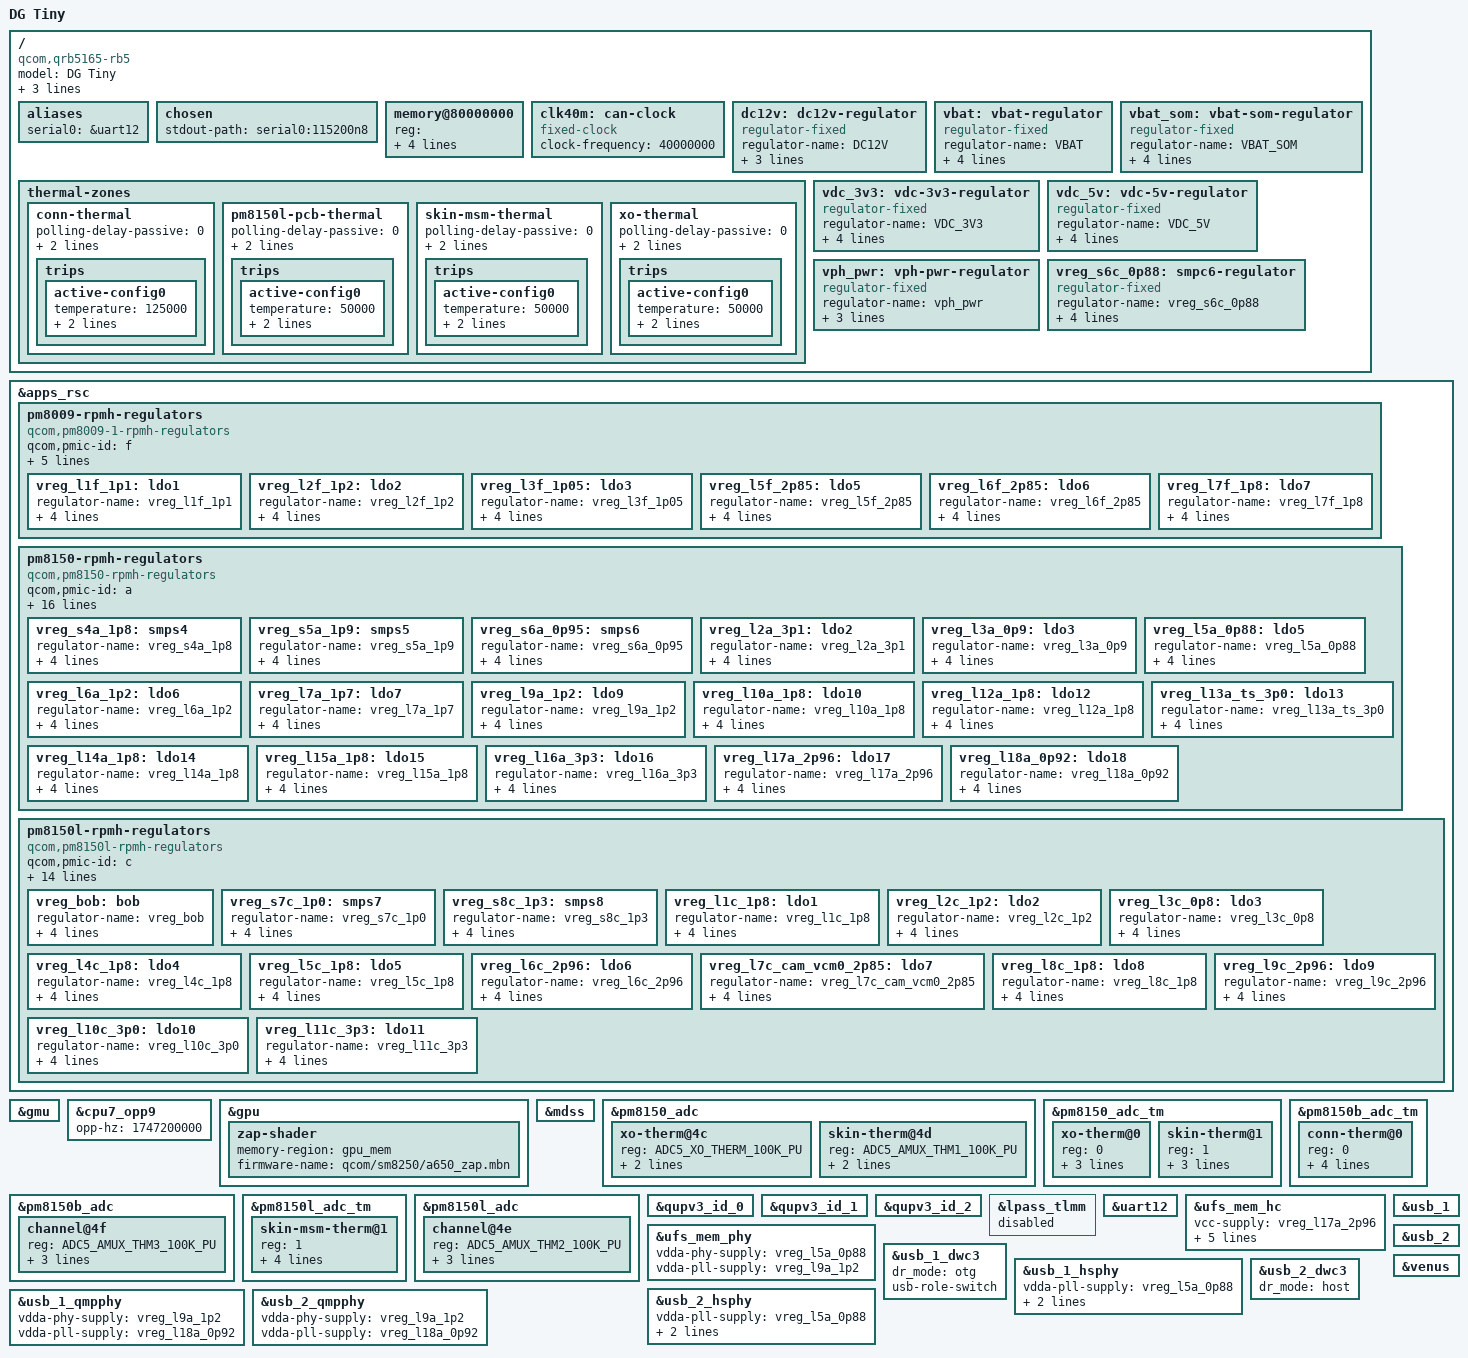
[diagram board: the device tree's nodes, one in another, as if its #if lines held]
// SPDX-License-Identifier: BSD-3-Clause

/dts-v1/;

#include <dt-bindings/regulator/qcom,rpmh-regulator.h>
#include <dt-bindings/leds/common.h>
#include <dt-bindings/pinctrl/qcom,pmic-gpio.h>
#include <dt-bindings/sound/qcom,q6afe.h>
#include <dt-bindings/sound/qcom,q6asm.h>
#include <dt-bindings/gpio/gpio.h>
#include "sm8250.dtsi"
#include "pm8150.dtsi"
#include "pm8150b.dtsi"
#include "pm8150l.dtsi"
#include "pm8009.dtsi"

/ {
	model = "DG Tiny";
	compatible = "qcom,qrb5165-rb5", "qcom,sm8250";
	qcom,msm-id = <455 0x20001>;
	qcom,board-id = <11 3>;
	chassis-type = "embedded";

	aliases {
		serial0 = &uart12;
	};

	chosen {
		stdout-path = "serial0:115200n8";
	};

#ifdef CONFIG_SYS_PROMPT
	memory@80000000 {
		device_type = "memory";
		reg = <0x00000000 0x80000000 0x00000000 0x39600000>, // 918 MB @ 0x80000000
			  <0x00000000 0xC0000000 0x00000000 0x14000000>, // 320 MB @ 0xC0000000
			  <0x00000001 0x00000000 0x00000001 0x30000000>, // 4.5 GB @ 0x100000000
			  <0x00000002 0x00000000 0x00000001 0x80000000>; // 6 GB @ 0x200000000
	};
#endif

	/* Fixed crystal oscillator dedicated to MCP2518FD */
	clk40m: can-clock {
		compatible = "fixed-clock";
		#clock-cells = <0>;
		clock-frequency = <40000000>;
	};

	dc12v: dc12v-regulator {
		compatible = "regulator-fixed";
		regulator-name = "DC12V";
		regulator-min-microvolt = <12000000>;
		regulator-max-microvolt = <12000000>;
		regulator-always-on;
	};

	thermal-zones {
		conn-thermal {
			polling-delay-passive = <0>;
			polling-delay = <0>;
			thermal-sensors = <&pm8150b_adc_tm 0>;

			trips {
				active-config0 {
					temperature = <125000>;
					hysteresis = <1000>;
					type = "critical";
				};
			};
		};

		pm8150l-pcb-thermal {
			polling-delay-passive = <0>;
			polling-delay = <0>;
			thermal-sensors = <&pm8150l_adc_tm 1>;

			trips {
				active-config0 {
					temperature = <50000>;
					hysteresis = <4000>;
					type = "passive";
				};
			};
		};

		skin-msm-thermal {
			polling-delay-passive = <0>;
			polling-delay = <0>;
			thermal-sensors = <&pm8150l_adc_tm 0>;

			trips {
				active-config0 {
					temperature = <50000>;
					hysteresis = <4000>;
					type = "passive";
				};
			};
		};

		xo-thermal {
			polling-delay-passive = <0>;
			polling-delay = <0>;
			thermal-sensors = <&pm8150_adc_tm 0>;

			trips {
				active-config0 {
					temperature = <50000>;
					hysteresis = <4000>;
					type = "passive";
				};
			};
		};
	};

	vbat: vbat-regulator {
		compatible = "regulator-fixed";
		regulator-name = "VBAT";
		vin-supply = <&vreg_l11c_3p3>;
		regulator-min-microvolt = <4200000>;
		regulator-max-microvolt = <4200000>;
		regulator-always-on;
	};

	vbat_som: vbat-som-regulator {
		compatible = "regulator-fixed";
		regulator-name = "VBAT_SOM";
		vin-supply = <&dc12v>;
		regulator-min-microvolt = <4200000>;
		regulator-max-microvolt = <4200000>;
		regulator-always-on;
	};

	vdc_3v3: vdc-3v3-regulator {
		compatible = "regulator-fixed";
		regulator-name = "VDC_3V3";
		vin-supply = <&vreg_l11c_3p3>;
		regulator-min-microvolt = <3300000>;
		regulator-max-microvolt = <3300000>;
		regulator-always-on;
	};

	vdc_5v: vdc-5v-regulator {
		compatible = "regulator-fixed";
		regulator-name = "VDC_5V";

		regulator-min-microvolt = <5000000>;
		regulator-max-microvolt = <5000000>;
		regulator-always-on;
		vin-supply = <&vreg_l11c_3p3>;
	};

	vph_pwr: vph-pwr-regulator {
		compatible = "regulator-fixed";
		regulator-name = "vph_pwr";
		regulator-min-microvolt = <3700000>;
		regulator-max-microvolt = <3700000>;
		regulator-always-on;
	};
/*
	vreg_s4a_1p8: vreg-s4a-1p8 {
		compatible = "regulator-fixed";
		regulator-name = "vreg_s4a_1p8";
		regulator-min-microvolt = <1800000>;
		regulator-max-microvolt = <1800000>;
		regulator-always-on;
	};
*/
	vreg_s6c_0p88: smpc6-regulator {
		compatible = "regulator-fixed";
		regulator-name = "vreg_s6c_0p88";

		regulator-min-microvolt = <880000>;
		regulator-max-microvolt = <880000>;
		regulator-always-on;
		vin-supply = <&vph_pwr>;
	};
};

&apps_rsc {
	pm8009-rpmh-regulators {
		compatible = "qcom,pm8009-1-rpmh-regulators";
		qcom,pmic-id = "f";

		vdd-s1-supply = <&vph_pwr>;
		vdd-s2-supply = <&vph_pwr>;
		vdd-l2-supply = <&vreg_s8c_1p3>;
		vdd-l5-l6-supply = <&vreg_bob>;
		vdd-l7-supply = <&vreg_s4a_1p8>;

		vreg_l1f_1p1: ldo1 {
			regulator-name = "vreg_l1f_1p1"; // bsp
			regulator-min-microvolt = <1104000>;
			regulator-max-microvolt = <1104000>;
			regulator-initial-mode = <RPMH_REGULATOR_MODE_HPM>;
		};

		vreg_l2f_1p2: ldo2 {
			regulator-name = "vreg_l2f_1p2"; // bsp
			regulator-min-microvolt = <1200000>;
			regulator-max-microvolt = <1200000>;
			regulator-initial-mode = <RPMH_REGULATOR_MODE_HPM>;
		};

		vreg_l3f_1p05: ldo3 {
			regulator-name = "vreg_l3f_1p05"; // bsp
			regulator-min-microvolt = <1056000>;
			regulator-max-microvolt = <1056000>;
			regulator-initial-mode = <RPMH_REGULATOR_MODE_HPM>;
		};

		vreg_l5f_2p85: ldo5 {
			regulator-name = "vreg_l5f_2p85"; // bsp
			regulator-min-microvolt = <2800000>;
			regulator-max-microvolt = <3000000>;
			regulator-initial-mode = <RPMH_REGULATOR_MODE_HPM>;
		};

		vreg_l6f_2p85: ldo6 {
			regulator-name = "vreg_l6f_2p85"; // bsp
			regulator-min-microvolt = <2800000>;
			regulator-max-microvolt = <3000000>;
			regulator-initial-mode = <RPMH_REGULATOR_MODE_HPM>;
		};

		vreg_l7f_1p8: ldo7 {
			regulator-name = "vreg_l7f_1p8"; // bsp
			regulator-min-microvolt = <1800000>;
			regulator-max-microvolt = <1800000>;
			regulator-initial-mode = <RPMH_REGULATOR_MODE_HPM>;
		};
	};

	pm8150-rpmh-regulators {
		compatible = "qcom,pm8150-rpmh-regulators";
		qcom,pmic-id = "a";

		vdd-s1-supply = <&vph_pwr>;
		vdd-s2-supply = <&vph_pwr>;
		vdd-s3-supply = <&vph_pwr>;
		vdd-s4-supply = <&vph_pwr>;
		vdd-s5-supply = <&vph_pwr>;
		vdd-s6-supply = <&vph_pwr>;
		vdd-s7-supply = <&vph_pwr>;
		vdd-s8-supply = <&vph_pwr>;
		vdd-s9-supply = <&vph_pwr>;
		vdd-s10-supply = <&vph_pwr>;
		vdd-l1-l8-l11-supply = <&vreg_s6c_0p88>;
		vdd-l2-l10-supply = <&vreg_bob>;
		vdd-l3-l4-l5-l18-supply = <&vreg_s6a_0p95>;
		vdd-l6-l9-supply = <&vreg_s8c_1p3>;
		vdd-l7-l12-l14-l15-supply = <&vreg_s5a_1p9>;
		vdd-l13-l16-l17-supply = <&vreg_bob>;

		vreg_s4a_1p8: smps4 {
			regulator-name = "vreg_s4a_1p8"; // bsp
			regulator-min-microvolt = <1800000>;
			regulator-max-microvolt = <1920000>;
			regulator-initial-mode = <RPMH_REGULATOR_MODE_HPM>;
		};

		vreg_s5a_1p9: smps5 {
			regulator-name = "vreg_s5a_1p9"; // bsp
			regulator-min-microvolt = <1824000>;
			regulator-max-microvolt = <2040000>;
			regulator-initial-mode = <RPMH_REGULATOR_MODE_HPM>;
		};

		vreg_s6a_0p95: smps6 {
			regulator-name = "vreg_s6a_0p95"; // bsp
			regulator-min-microvolt = <600000>;
			regulator-max-microvolt = <1128000>;
			regulator-initial-mode = <RPMH_REGULATOR_MODE_HPM>;
		};

		vreg_l2a_3p1: ldo2 {
			regulator-name = "vreg_l2a_3p1"; // bsp
			regulator-min-microvolt = <3072000>;
			regulator-max-microvolt = <3072000>;
			regulator-initial-mode = <RPMH_REGULATOR_MODE_HPM>;
		};

		vreg_l3a_0p9: ldo3 {
			regulator-name = "vreg_l3a_0p9"; // bsp
			regulator-min-microvolt = <928000>;
			regulator-max-microvolt = <932000>;
			regulator-initial-mode = <RPMH_REGULATOR_MODE_HPM>;
		};

		vreg_l5a_0p88: ldo5 {
			regulator-name = "vreg_l5a_0p88"; // bsp
			regulator-min-microvolt = <880000>;
			regulator-max-microvolt = <880000>;
			regulator-initial-mode = <RPMH_REGULATOR_MODE_HPM>;
		};

		vreg_l6a_1p2: ldo6 {
			regulator-name = "vreg_l6a_1p2"; // bsp
			regulator-min-microvolt = <1200000>;
			regulator-max-microvolt = <1200000>;
			regulator-initial-mode = <RPMH_REGULATOR_MODE_HPM>;
		};

		vreg_l7a_1p7: ldo7 {
			regulator-name = "vreg_l7a_1p7"; // bsp
			regulator-min-microvolt = <1704000>;
			regulator-max-microvolt = <1800000>;
			regulator-initial-mode = <RPMH_REGULATOR_MODE_HPM>;
		};

		vreg_l9a_1p2: ldo9 {
			regulator-name = "vreg_l9a_1p2"; // bsp
			regulator-min-microvolt = <1200000>;
			regulator-max-microvolt = <1200000>;
			regulator-initial-mode = <RPMH_REGULATOR_MODE_HPM>;
		};

		vreg_l10a_1p8: ldo10 {
			regulator-name = "vreg_l10a_1p8"; // bsp
			regulator-min-microvolt = <1800000>;
			regulator-max-microvolt = <2960000>;
			regulator-initial-mode = <RPMH_REGULATOR_MODE_HPM>;
		};

		vreg_l12a_1p8: ldo12 {
			regulator-name = "vreg_l12a_1p8"; // bsp
			regulator-min-microvolt = <1800000>;
			regulator-max-microvolt = <1800000>;
			regulator-initial-mode = <RPMH_REGULATOR_MODE_HPM>;
		};

		vreg_l13a_ts_3p0: ldo13 {
			regulator-name = "vreg_l13a_ts_3p0"; // bsp
			regulator-min-microvolt = <3008000>;
			regulator-max-microvolt = <3008000>;
			regulator-initial-mode = <RPMH_REGULATOR_MODE_HPM>;
		};

		vreg_l14a_1p8: ldo14 {
			regulator-name = "vreg_l14a_1p8"; // bsp
			regulator-min-microvolt = <1800000>;
			regulator-max-microvolt = <1880000>;
			regulator-initial-mode = <RPMH_REGULATOR_MODE_HPM>;
		};

		vreg_l15a_1p8: ldo15 {
			regulator-name = "vreg_l15a_1p8"; // bsp
			regulator-min-microvolt = <1800000>;
			regulator-max-microvolt = <1800000>;
			regulator-initial-mode = <RPMH_REGULATOR_MODE_HPM>;
		};

		vreg_l16a_3p3: ldo16 {
			regulator-name = "vreg_l16a_3p3"; // bsp
			regulator-min-microvolt = <3024000>;
			regulator-max-microvolt = <3304000>;
			regulator-initial-mode = <RPMH_REGULATOR_MODE_HPM>;
		};

		vreg_l17a_2p96: ldo17 {
			regulator-name = "vreg_l17a_2p96"; // bsp
			regulator-min-microvolt = <2496000>;
			regulator-max-microvolt = <3008000>;
			regulator-initial-mode = <RPMH_REGULATOR_MODE_HPM>;
		};

		vreg_l18a_0p92: ldo18 {
			regulator-name = "vreg_l18a_0p92"; // bsp
			regulator-min-microvolt = <800000>;
			regulator-max-microvolt = <920000>;
			regulator-initial-mode = <RPMH_REGULATOR_MODE_HPM>;
		};
	};

	pm8150l-rpmh-regulators {
		compatible = "qcom,pm8150l-rpmh-regulators";
		qcom,pmic-id = "c";

		vdd-s1-supply = <&vph_pwr>;
		vdd-s2-supply = <&vph_pwr>;
		vdd-s3-supply = <&vph_pwr>;
		vdd-s4-supply = <&vph_pwr>;
		vdd-s5-supply = <&vph_pwr>;
		vdd-s6-supply = <&vph_pwr>;
		vdd-s7-supply = <&vph_pwr>;
		vdd-s8-supply = <&vph_pwr>;
		vdd-l1-l8-supply = <&vreg_s4a_1p8>;
		vdd-l2-l3-supply = <&vreg_s8c_1p3>;
		vdd-l4-l5-l6-supply = <&vreg_bob>;
		vdd-l7-l11-supply = <&vreg_bob>;
		vdd-l9-l10-supply = <&vreg_bob>;
		vdd-bob-supply = <&vph_pwr>;

		vreg_bob: bob {
			regulator-name = "vreg_bob"; // bsp
			regulator-min-microvolt = <3008000>;
			regulator-max-microvolt = <3960000>;
			regulator-initial-mode = <RPMH_REGULATOR_MODE_AUTO>;
		};

		vreg_s7c_1p0: smps7 {
			regulator-name = "vreg_s7c_1p0"; // bsp
			regulator-min-microvolt = <348000>;
			regulator-max-microvolt = <1000000>;
			regulator-initial-mode = <RPMH_REGULATOR_MODE_HPM>;
		};

		vreg_s8c_1p3: smps8 {
			regulator-name = "vreg_s8c_1p3"; // bsp
			regulator-min-microvolt = <1200000>;
			regulator-max-microvolt = <1400000>;
			regulator-initial-mode = <RPMH_REGULATOR_MODE_HPM>;
		};

		vreg_l1c_1p8: ldo1 {
			regulator-name = "vreg_l1c_1p8"; // bsp
			regulator-min-microvolt = <1800000>;
			regulator-max-microvolt = <1800000>;
			regulator-initial-mode = <RPMH_REGULATOR_MODE_HPM>;
		};

		vreg_l2c_1p2: ldo2 {
			regulator-name = "vreg_l2c_1p2"; // bsp
			regulator-min-microvolt = <1200000>;
			regulator-max-microvolt = <1304000>;
			regulator-initial-mode = <RPMH_REGULATOR_MODE_HPM>;
		};

		vreg_l3c_0p8: ldo3 {
			regulator-name = "vreg_l3c_0p8"; // bsp
			regulator-min-microvolt = <800000>;
			regulator-max-microvolt = <1200000>;
			regulator-initial-mode = <RPMH_REGULATOR_MODE_HPM>;
		};

		vreg_l4c_1p8: ldo4 {
			regulator-name = "vreg_l4c_1p8"; // bsp
			regulator-min-microvolt = <1800000>;
			regulator-max-microvolt = <2800000>;
			regulator-initial-mode = <RPMH_REGULATOR_MODE_HPM>;
		};

		vreg_l5c_1p8: ldo5 {
			regulator-name = "vreg_l5c_1p8"; // bsp
			regulator-min-microvolt = <1800000>;
			regulator-max-microvolt = <2800000>;
			regulator-initial-mode = <RPMH_REGULATOR_MODE_HPM>;
		};

		vreg_l6c_2p96: ldo6 {
			regulator-name = "vreg_l6c_2p96"; // bsp
			regulator-min-microvolt = <1800000>;
			regulator-max-microvolt = <2960000>;
			regulator-initial-mode = <RPMH_REGULATOR_MODE_HPM>;
		};

		vreg_l7c_cam_vcm0_2p85: ldo7 {
			regulator-name = "vreg_l7c_cam_vcm0_2p85"; // bsp
			regulator-min-microvolt = <2856000>;
			regulator-max-microvolt = <3104000>;
			regulator-initial-mode = <RPMH_REGULATOR_MODE_HPM>;
		};

		vreg_l8c_1p8: ldo8 {
			regulator-name = "vreg_l8c_1p8"; // bsp
			regulator-min-microvolt = <1800000>;
			regulator-max-microvolt = <1800000>;
			regulator-initial-mode = <RPMH_REGULATOR_MODE_HPM>;
		};

		vreg_l9c_2p96: ldo9 {
			regulator-name = "vreg_l9c_2p96"; // bsp
			regulator-min-microvolt = <2704000>;
			regulator-max-microvolt = <2960000>;
			regulator-initial-mode = <RPMH_REGULATOR_MODE_HPM>;
		};

		vreg_l10c_3p0: ldo10 {
			regulator-name = "vreg_l10c_3p0"; // bsp
			regulator-min-microvolt = <3000000>;
			regulator-max-microvolt = <3312000>;
			regulator-initial-mode = <RPMH_REGULATOR_MODE_HPM>;
		};

		vreg_l11c_3p3: ldo11 {
			regulator-name = "vreg_l11c_3p3"; // bsp
			regulator-min-microvolt = <3104000>;
			regulator-max-microvolt = <3312000>;
			regulator-initial-mode = <RPMH_REGULATOR_MODE_HPM>;
		};
	};
};

// &slpi {
// 	status = "okay";
// 	firmware-name = "qcom/sm8250/Thundercomm/RB5/slpi.mbn";
// };

// &adsp {
// 	status = "okay";
// 	firmware-name = "qcom/sm8250/adsp.mbn";
// };

// &cdsp {
// 	status = "okay";
// 	firmware-name = "qcom/sm8250/cdsp.mbn";
// };

&gmu {
	status = "okay";
};

&cpu7_opp9 {
	opp-hz = /bits/ 64 <1747200000>;
};

&gpu {
	status = "okay";

	zap-shader {
		memory-region = <&gpu_mem>;
		firmware-name = "qcom/sm8250/a650_zap.mbn";
	};
};

&mdss {
	status = "okay";
};

&pm8150_adc {
	xo-therm@4c {
		reg = <ADC5_XO_THERM_100K_PU>;
		qcom,ratiometric;
		qcom,hw-settle-time = <200>;
	};

	skin-therm@4d {
		reg = <ADC5_AMUX_THM1_100K_PU>;
		qcom,ratiometric;
		qcom,hw-settle-time = <200>;
	};
};

&pm8150_adc_tm {
	status = "okay";

	xo-therm@0 {
		reg = <0>;
		io-channels = <&pm8150_adc ADC5_XO_THERM_100K_PU>;
		qcom,ratiometric;
		qcom,hw-settle-time-us = <200>;
	};

	skin-therm@1 {
		reg = <1>;
		io-channels = <&pm8150_adc ADC5_AMUX_THM1_100K_PU>;
		qcom,ratiometric;
		qcom,hw-settle-time-us = <200>;
	};
};

&pm8150b_adc {
	channel@4f {
		reg = <ADC5_AMUX_THM3_100K_PU>;
		qcom,ratiometric;
		qcom,hw-settle-time = <200>;
		label = "conn_therm";
	};
};

&pm8150b_adc_tm {
	status = "okay";

	conn-therm@0 {
		reg = <0>;
		io-channels = <&pm8150b_adc ADC5_AMUX_THM3_100K_PU>;
		qcom,ratiometric;
		qcom,hw-settle-time-us = <200>;
	};
};

&pm8150l_adc_tm {
	status = "okay";

	skin-msm-therm@1 {
		reg = <1>;
		io-channels = <&pm8150l_adc ADC5_AMUX_THM2_100K_PU>;
		qcom,ratiometric;
		qcom,hw-settle-time-us = <200>;
	};
};

&pm8150l_adc {
	channel@4e {
		reg = <ADC5_AMUX_THM2_100K_PU>;
		qcom,ratiometric;
		qcom,hw-settle-time = <200>;
		label = "skin_msm_therm";
	};
};

&qupv3_id_0 {
	status = "okay";
};

&qupv3_id_1 {
	status = "okay";
};

&qupv3_id_2 {
	status = "okay";
};

&lpass_tlmm {
	status = "disabled";
};

&uart12 {
	status = "okay";
};

&ufs_mem_hc {
	status = "okay";

	vcc-supply = <&vreg_l17a_2p96>;
	vcc-max-microamp = <800000>;
	vccq-supply = <&vreg_l6a_1p2>;
	vccq-max-microamp = <800000>;
	vccq2-supply = <&vreg_s4a_1p8>;
	vccq2-max-microamp = <800000>;
};

&ufs_mem_phy {
	status = "okay";

	vdda-phy-supply = <&vreg_l5a_0p88>;
	vdda-pll-supply = <&vreg_l9a_1p2>;
};

&usb_1 {
	status = "okay";
};

&usb_1_dwc3 {
	dr_mode = "otg";
	usb-role-switch;
};

&usb_1_hsphy {
	status = "okay";

	vdda-pll-supply = <&vreg_l5a_0p88>;
	vdda33-supply = <&vreg_l2a_3p1>;
	vdda18-supply = <&vreg_l12a_1p8>;
};

&usb_1_qmpphy {
	status = "okay";

	vdda-phy-supply = <&vreg_l9a_1p2>;
	vdda-pll-supply = <&vreg_l18a_0p92>;
};

&usb_2 {
	status = "okay";
};

&usb_2_dwc3 {
	dr_mode = "host";
};

&usb_2_hsphy {
	status = "okay";

	vdda-pll-supply = <&vreg_l5a_0p88>;
	vdda33-supply = <&vreg_l2a_3p1>;
	vdda18-supply = <&vreg_l12a_1p8>;
};

&usb_2_qmpphy {
	status = "okay";

	vdda-phy-supply = <&vreg_l9a_1p2>;
	vdda-pll-supply = <&vreg_l18a_0p92>;
};

&venus {
	status = "okay";
};
